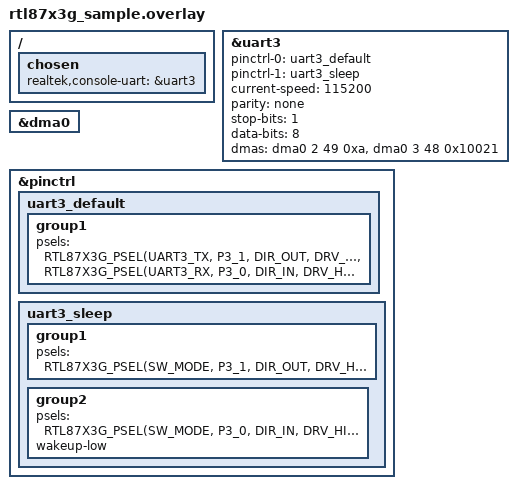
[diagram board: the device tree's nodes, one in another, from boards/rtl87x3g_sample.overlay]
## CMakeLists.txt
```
#
# Copyright (c) 2026, Realtek Semiconductor Corporation
#
# SPDX-License-Identifier: LicenseRef-Realtek-5-Clause
#

message(STATUS "CMAKELIST FOLDER: ${CMAKE_CURRENT_SOURCE_DIR}")

cmake_minimum_required(VERSION 3.20.0)

#===========version generation===========
include(${CMAKE_CURRENT_SOURCE_DIR}/../../cmake/version_generate.cmake)
generate_version()
#===========version generation===========
#===========post build===========
# post build should be called before find_package
include(${CMAKE_CURRENT_SOURCE_DIR}/../../cmake/post_build.cmake)
rtk_post_build()
#===========post build===========

find_package(Zephyr REQUIRED HINTS $ENV{ZEPHYR_BASE})
project(bt_audio)

FILE(GLOB app_sources src/*.c)
target_sources(app PRIVATE
  ${app_sources}
  )

set(sources
   ${ZEPHYR_REALTEK_APP_MODULE_DIR}/common/console/transport/console_uart.c
   )

set(headers
    #header files from app
	  src/
    #header files from libs
    ${ZEPHYR_REALTEK_APP_MODULE_DIR}/../modules/hal/realtek/rtl87x3g/subsys/audio/inc
    ${ZEPHYR_REALTEK_APP_MODULE_DIR}/../modules/hal/realtek/rtl87x3g/subsys/console/inc
    ${ZEPHYR_REALTEK_APP_MODULE_DIR}/common/console/transport
    ${ZEPHYR_REALTEK_APP_MODULE_DIR}/samples/bt_audio
    )  

foreach(header ${headers})
    if(EXISTS ${header})
        zephyr_include_directories(${header})
    else()
        message(FATAL_ERROR "header file directory does not exist: ${header}. Current cmakelist: ${CMAKE_CURRENT_SOURCE_DIR}")
    endif()
endforeach()

foreach(src ${sources})
    if(EXISTS ${src})
        target_sources(app PRIVATE ${src})
    else()
        message(FATAL_ERROR "source file does not exist: ${src}. Current cmakelist: ${CMAKE_CURRENT_SOURCE_DIR}")
    endif()
endforeach()

target_precompile_headers(app PUBLIC
	          ${CMAKE_CURRENT_SOURCE_DIR}/src/app_flags.h
			  )

target_include_directories(app PRIVATE src)

target_compile_definitions(app PRIVATE CONFIG_SOC_SERIES_RTL8773G=1)
```

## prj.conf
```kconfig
CONFIG_SERIAL=y

# Use realtek console with uart dma 
# the dma node should be added in uart node
CONFIG_UART_ASYNC_API=y
# Use realtek console with uart interrupt
# CONFIG_UART_INTERRUPT_DRIVEN=y

CONFIG_REALTEK_SUBSYS_SYSM=y
CONFIG_REALTEK_SUBSYS_CONSOLE=y
CONFIG_REALTEK_SUBSYS_REMOTE=y
CONFIG_REALTEK_SUBSYS_BTM=y
CONFIG_REALTEK_SUBSYS_AUDIO=y
CONFIG_HEAP_MEM_POOL_SIZE=1024
```

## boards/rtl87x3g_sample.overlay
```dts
/*
 * Copyright(c) 2024, Realtek Semiconductor Corporation.
 *
 * SPDX-License-Identifier: Apache-2.0
 */

/ {
    chosen {
        /* Route the RTK console transport onto uart3 through the Zephyr async
         * UART driver. Change this phandle to move the console to any UART. */
        realtek,console-uart = &uart3;
    };
};

&uart3 {
    pinctrl-0 = <&uart3_default>;
    pinctrl-1 = <&uart3_sleep>;
    pinctrl-names = "default", "sleep";
    status = "okay";
    current-speed = <115200>;
    parity = "none";
    stop-bits = "1";
    data-bits = <8>;
    dmas = <&dma0 2 49 0xa>, <&dma0 3 48 0x10021>;
    dma-names = "rx", "tx";
};

&dma0 {
    status = "okay";
};

&pinctrl
{
    uart3_default:uart3_default {
        group1 {
            psels = <RTL87X3G_PSEL(UART3_TX, P3_1, DIR_OUT, DRV_HIGH, PULL_UP)>,
            <RTL87X3G_PSEL(UART3_RX, P3_0, DIR_IN, DRV_HIGH, PULL_UP)>;
        };
    };

    uart3_sleep:uart3_sleep {
        group1 {
            psels = <RTL87X3G_PSEL(SW_MODE, P3_1, DIR_OUT, DRV_HIGH, PULL_UP)>;
        };
        group2 {
            psels = <RTL87X3G_PSEL(SW_MODE, P3_0, DIR_IN, DRV_HIGH, PULL_UP)>;
            wakeup-low;
        };
    };
};
```

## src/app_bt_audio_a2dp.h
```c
/*
 * Copyright (c) 2026, Realtek Semiconductor Corporation
 *
 * SPDX-License-Identifier: LicenseRef-Realtek-5-Clause
 */

#ifndef _APP_BT_AUDIO_A2DP_H_
#define _APP_BT_AUDIO_A2DP_H_

#include "app_msg.h"

#ifdef __cplusplus
extern "C" {
#endif /* __cplusplus */

/** @defgroup APP_BT_AUDIO_A2DP BT Audio A2DP
* @brief APP BT Audio A2DP
* @{
*/

/*============================================================================*
 *                         Macros
 *============================================================================*/
/** @addtogroup APP_BT_AUDIO_A2DP_Exported_Macros BT Audio A2DP Exported Macros
  * @brief
  * @{
  */



/** End of APP_BT_AUDIO_A2DP_Exported_Macros
* @}
*/

/*============================================================================*
 *                         Functions
 *============================================================================*/
/** @defgroup APP_BT_AUDIO_A2DP_Exported_Functions BT Audio A2DP Exported Functions
  * @brief
  * @{
  */

void app_bt_audio_a2dp_init(uint8_t role);

void app_bt_audio_a2dp_handle_msg(T_IO_MSG msg);

bool app_bt_audio_a2dp_connect(uint8_t *bd_addr);

bool app_bt_audio_a2dp_disconnect(uint8_t *bd_addr);

bool app_bt_audio_a2dp_start(uint8_t *bd_addr);

bool app_bt_audio_a2dp_suspend(uint8_t *bd_addr);

bool app_bt_audio_a2dp_volume_up(uint8_t *bd_addr);

bool app_bt_audio_a2dp_volume_down(uint8_t *bd_addr);

/** @} End of APP_BT_AUDIO_A2DP_Exported_Functions */

/** @} End of APP_BT_AUDIO_A2DP */

#ifdef __cplusplus
}
#endif /* __cplusplus */

#endif /* _APP_BT_AUDIO_A2DP_H_ */
```

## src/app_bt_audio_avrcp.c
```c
/*
 * Copyright (c) 2026, Realtek Semiconductor Corporation
 *
 * SPDX-License-Identifier: LicenseRef-Realtek-5-Clause
 */

#include <stdio.h>
#include <string.h>
#include "trace.h"
#include "console.h"
#include "audio.h"
#include "btm.h"
#include "bt_types.h"
#include "bt_sdp.h"
#include "bt_a2dp.h"
#include "bt_avrcp.h"
#include "app_bt_audio_link.h"
#include "app_bt_audio_avrcp.h"

#if (BT_AUDIO_DEMO_ROLE == 1)
static const uint8_t avrcp_ct_sdp_record[] =
{
    //Total length
    SDP_DATA_ELEM_SEQ_HDR,
    0x3b,

    //Attribute SDP_ATTR_SRV_CLASS_ID_LIST
    SDP_UNSIGNED_TWO_BYTE,
    (uint8_t)(SDP_ATTR_SRV_CLASS_ID_LIST >> 8),
    (uint8_t)SDP_ATTR_SRV_CLASS_ID_LIST,
    SDP_DATA_ELEM_SEQ_HDR,
    0x06, //Attribute length: 6 bytes
    //Service Class #0: A/V Remote Control
    SDP_UUID16_HDR,
    (uint8_t)(UUID_AV_REMOTE_CONTROL >> 8),
    (uint8_t)(UUID_AV_REMOTE_CONTROL),
    SDP_UUID16_HDR,
    (uint8_t)(UUID_AV_REMOTE_CONTROL_CONTROLLER >> 8),
    (uint8_t)(UUID_AV_REMOTE_CONTROL_CONTROLLER & 0xff),
    //Service Class #1: A/V Remote Control Controller

    //Attribute SDP_ATTR_PROTO_DESC_LIST
    SDP_UNSIGNED_TWO_BYTE,
    (uint8_t)(SDP_ATTR_PROTO_DESC_LIST >> 8),
    (uint8_t)SDP_ATTR_PROTO_DESC_LIST,
    SDP_DATA_ELEM_SEQ_HDR,
    0x10, //Attribute length: 16 bytes
    //Protocol #0: L2CAP
    SDP_DATA_ELEM_SEQ_HDR,
    0x06, //Element length: 3 bytes
    SDP_UUID16_HDR,
    (uint8_t)(UUID_L2CAP >> 8),
    (uint8_t)(UUID_L2CAP),
    //Parameter #0 for Protocol #0: PSM = AVCTP
    SDP_UNSIGNED_TWO_BYTE,
    (uint8_t)(PSM_AVCTP >> 8),
    (uint8_t)PSM_AVCTP,
    //Protocol #1: AVCTP
    SDP_DATA_ELEM_SEQ_HDR,
    0x06, //Element length: 5 bytes
    SDP_UUID16_HDR,
    (uint8_t)(UUID_AVCTP >> 8),
    (uint8_t)(UUID_AVCTP),
    //Parameter #0 for Protocol #1: 0x0104 (v1.4)
    SDP_UNSIGNED_TWO_BYTE,
    (uint8_t)(0x0104 >> 8),
    (uint8_t)(0x0104),

    //Attribute SDP_ATTR_PROFILE_DESC_LIST
    SDP_UNSIGNED_TWO_BYTE,
    (uint8_t)(SDP_ATTR_PROFILE_DESC_LIST >> 8),
    (uint8_t)SDP_ATTR_PROFILE_DESC_LIST,
    SDP_DATA_ELEM_SEQ_HDR,
    0x08, //Attribute length: 8 bytes
    //Profile #0: A/V Remote Control
    SDP_DATA_ELEM_SEQ_HDR,
    0x06, //Element length: 6 bytes
    SDP_UUID16_HDR,
    (uint8_t)(UUID_AV_REMOTE_CONTROL >> 8),
    (uint8_t)(UUID_AV_REMOTE_CONTROL),
    //Parameter #0 for Profile #0: 0x0106 (v1.6)
    SDP_UNSIGNED_TWO_BYTE,
    (uint8_t)(0x0106 >> 8),
    (uint8_t)(0x0106),

    //Attribute SDP_ATTR_SUPPORTED_FEATURES
    SDP_UNSIGNED_TWO_BYTE,
    (uint8_t)((SDP_ATTR_SUPPORTED_FEATURES) >> 8),
    (uint8_t)(SDP_ATTR_SUPPORTED_FEATURES),
    SDP_UNSIGNED_TWO_BYTE,
    (uint8_t)(0x0003 >> 8), //Category 1 Player / Recorder, Category 2
    (uint8_t)(0x0003 & 0xff),

    //Attribute SDP_ATTR_BROWSE_GROUP_LIST
    SDP_UNSIGNED_TWO_BYTE,
    (uint8_t)(SDP_ATTR_BROWSE_GROUP_LIST >> 8),
    (uint8_t)SDP_ATTR_BROWSE_GROUP_LIST,
    SDP_DATA_ELEM_SEQ_HDR,
    0x03,
    SDP_UUID16_HDR,
    (uint8_t)(UUID_PUBLIC_BROWSE_GROUP >> 8),
    (uint8_t)UUID_PUBLIC_BROWSE_GROUP
};

static const uint8_t avrcp_tg_sdp_record[] =
{
    //Total length
    SDP_DATA_ELEM_SEQ_HDR,
    0x38,//0x46,//0x5F,

    //Attribute SDP_ATTR_SRV_CLASS_ID_LIST
    SDP_UNSIGNED_TWO_BYTE,
    (uint8_t)(SDP_ATTR_SRV_CLASS_ID_LIST >> 8),
    (uint8_t)SDP_ATTR_SRV_CLASS_ID_LIST,
    SDP_DATA_ELEM_SEQ_HDR,
    0x03, //Attribute length: 3 bytes
    //Service Class #0: A/V Remote Control Target
    SDP_UUID16_HDR,
    (uint8_t)(UUID_AV_REMOTE_CONTROL_TARGET >> 8),
    (uint8_t)(UUID_AV_REMOTE_CONTROL_TARGET),

    //Attribute SDP_ATTR_PROTO_DESC_LIST
    SDP_UNSIGNED_TWO_BYTE,
    (uint8_t)(SDP_ATTR_PROTO_DESC_LIST >> 8),
    (uint8_t)SDP_ATTR_PROTO_DESC_LIST,
    SDP_DATA_ELEM_SEQ_HDR,
    0x10, //Attribute length: 16 bytes
    //Protocol #0: L2CAP
    SDP_DATA_ELEM_SEQ_HDR,
    0x06, //Element length: 3 bytes
    SDP_UUID16_HDR,
    (uint8_t)(UUID_L2CAP >> 8),
    (uint8_t)(UUID_L2CAP),
    //Parameter #0 for Protocol #0: PSM = AVCTP
    SDP_UNSIGNED_TWO_BYTE,
    (uint8_t)(PSM_AVCTP >> 8),
    (uint8_t)PSM_AVCTP,
    //Protocol #1: AVCTP
    SDP_DATA_ELEM_SEQ_HDR,
    0x06, //Element length: 5 bytes
    SDP_UUID16_HDR,
    (uint8_t)(UUID_AVCTP >> 8),
    (uint8_t)(UUID_AVCTP),
    //Parameter #0 for Protocol #1: 0x0104 (v1.4)
    SDP_UNSIGNED_TWO_BYTE,
    (uint8_t)(0x0104 >> 8),
    (uint8_t)(0x0104),

    //Attribute SDP_ATTR_PROFILE_DESC_LIST
    SDP_UNSIGNED_TWO_BYTE,
    (uint8_t)(SDP_ATTR_PROFILE_DESC_LIST >> 8),
    (uint8_t)SDP_ATTR_PROFILE_DESC_LIST,
    SDP_DATA_ELEM_SEQ_HDR,
    0x08, //Attribute length: 8 bytes
    //Profile #0: A/V Remote Control
    SDP_DATA_ELEM_SEQ_HDR,
    0x06, //Element length: 6 bytes
    SDP_UUID16_HDR,
    (uint8_t)(UUID_AV_REMOTE_CONTROL >> 8),
    (uint8_t)(UUID_AV_REMOTE_CONTROL),
    //Parameter #0 for Profile #0: 0x0106 (v1.6)
    SDP_UNSIGNED_TWO_BYTE,
    (uint8_t)(0x0106 >> 8),
    (uint8_t)(0x0106),

    //Attribute SDP_ATTR_SUPPORTED_FEATURES
    SDP_UNSIGNED_TWO_BYTE,
    (uint8_t)((SDP_ATTR_SUPPORTED_FEATURES) >> 8),
    (uint8_t)(SDP_ATTR_SUPPORTED_FEATURES),
    SDP_UNSIGNED_TWO_BYTE,
    (uint8_t)(0x0001 >> 8), //Category 1
    (uint8_t)(0x0001 & 0xff),

    //Attribute SDP_ATTR_BROWSE_GROUP_LIST
    SDP_UNSIGNED_TWO_BYTE,
    (uint8_t)(SDP_ATTR_BROWSE_GROUP_LIST >> 8),
    (uint8_t)SDP_ATTR_BROWSE_GROUP_LIST,
    SDP_DATA_ELEM_SEQ_HDR,
    0x03,
    SDP_UUID16_HDR,
    (uint8_t)(UUID_PUBLIC_BROWSE_GROUP >> 8),
    (uint8_t)UUID_PUBLIC_BROWSE_GROUP
};
#else
static const uint8_t avrcp_ct_sdp_record[] =
{
    //Total length
    SDP_DATA_ELEM_SEQ_HDR,
    0x3B,//0x49,//0x62,

    //Attribute SDP_ATTR_SRV_CLASS_ID_LIST
    SDP_UNSIGNED_TWO_BYTE,
    (uint8_t)(SDP_ATTR_SRV_CLASS_ID_LIST >> 8),
    (uint8_t)SDP_ATTR_SRV_CLASS_ID_LIST,
    SDP_DATA_ELEM_SEQ_HDR,
    0x06, //Attribute length: 6 bytes
    //Service Class #0: A/V Remote Control
    SDP_UUID16_HDR,
    (uint8_t)(UUID_AV_REMOTE_CONTROL >> 8),
    (uint8_t)(UUID_AV_REMOTE_CONTROL),
    //Service Class #1: A/V Remote Control Controller
    SDP_UUID16_HDR,
    (uint8_t)(UUID_AV_REMOTE_CONTROL_CONTROLLER >> 8),
    (uint8_t)(UUID_AV_REMOTE_CONTROL_CONTROLLER),

    //Attribute SDP_ATTR_PROTO_DESC_LIST
    SDP_UNSIGNED_TWO_BYTE,
    (uint8_t)(SDP_ATTR_PROTO_DESC_LIST >> 8),
    (uint8_t)SDP_ATTR_PROTO_DESC_LIST,
    SDP_DATA_ELEM_SEQ_HDR,
    0x10, //Attribute length: 12 bytes
    //Protocol #0: L2CAP
    SDP_DATA_ELEM_SEQ_HDR,
    0x06, //Element length: 3 bytes
    SDP_UUID16_HDR,
    (uint8_t)(UUID_L2CAP >> 8),
    (uint8_t)(UUID_L2CAP),
    //Parameter #0 for Protocol #0: PSM = AVCTP
    SDP_UNSIGNED_TWO_BYTE,
    (uint8_t)(PSM_AVCTP >> 8),
    (uint8_t)PSM_AVCTP,
    //Protocol #1: AVCTP
    SDP_DATA_ELEM_SEQ_HDR,
    0x06, //Element length: 5 bytes
    SDP_UUID16_HDR,
    (uint8_t)(UUID_AVCTP >> 8),
    (uint8_t)(UUID_AVCTP),
    //Parameter #0 for Protocol #1: 0x0104 (v1.4)
    SDP_UNSIGNED_TWO_BYTE,
    (uint8_t)(0x0104 >> 8),
    (uint8_t)(0x0104),

    //Attribute SDP_ATTR_PROFILE_DESC_LIST
    SDP_UNSIGNED_TWO_BYTE,
    (uint8_t)(SDP_ATTR_PROFILE_DESC_LIST >> 8),
    (uint8_t)SDP_ATTR_PROFILE_DESC_LIST,
    SDP_DATA_ELEM_SEQ_HDR,
    0x08, //Attribute length: 8 bytes
    //Profile #0: A/V Remote Control
    SDP_DATA_ELEM_SEQ_HDR,
    0x06, //Element length: 6 bytes
    SDP_UUID16_HDR,
    (uint8_t)(UUID_AV_REMOTE_CONTROL >> 8),
    (uint8_t)(UUID_AV_REMOTE_CONTROL),
    //Parameter #0 for Profile #0: 0x0106 (v1.6)
    SDP_UNSIGNED_TWO_BYTE,
    (uint8_t)(0x0106 >> 8),
    (uint8_t)(0x0106),

    //Attribute SDP_ATTR_SUPPORTED_FEATURES
    SDP_UNSIGNED_TWO_BYTE,
    (uint8_t)((SDP_ATTR_SUPPORTED_FEATURES) >> 8),
    (uint8_t)(SDP_ATTR_SUPPORTED_FEATURES),
    SDP_UNSIGNED_TWO_BYTE,
    (uint8_t)(0x0001 >> 8), //Category 1 Player / Recorder
    (uint8_t)(0x0001),

    //Attribute SDP_ATTR_BROWSE_GROUP_LIST
    SDP_UNSIGNED_TWO_BYTE,
    (uint8_t)(SDP_ATTR_BROWSE_GROUP_LIST >> 8),
    (uint8_t)SDP_ATTR_BROWSE_GROUP_LIST,
    SDP_DATA_ELEM_SEQ_HDR,
    0x03,
    SDP_UUID16_HDR,
    (uint8_t)(UUID_PUBLIC_BROWSE_GROUP >> 8),
    (uint8_t)UUID_PUBLIC_BROWSE_GROUP
    /*
        //Attribute SDP_ATTR_LANG_BASE_ATTR_ID_LIST...it is used for SDP_ATTR_SRV_NAME
        SDP_UNSIGNED_TWO_BYTE,
        (uint8_t)(SDP_ATTR_LANG_BASE_ATTR_ID_LIST >> 8),
        (uint8_t)SDP_ATTR_LANG_BASE_ATTR_ID_LIST,
        SDP_DATA_ELEM_SEQ_HDR,
        0x09,
        SDP_UNSIGNED_TWO_BYTE,
        (uint8_t)(SDP_LANG_ENGLISH >> 8),
        (uint8_t)SDP_LANG_ENGLISH,
        SDP_UNSIGNED_TWO_BYTE,
        (uint8_t)(SDP_CHARACTER_UTF8 >> 8),
        (uint8_t)SDP_CHARACTER_UTF8,
        SDP_UNSIGNED_TWO_BYTE,
        (uint8_t)(SDP_BASE_LANG_OFFSET >> 8),
        (uint8_t)SDP_BASE_LANG_OFFSET,

        //Attribute SDP_ATTR_PROVIDER_NAME
        SDP_UNSIGNED_TWO_BYTE,
        (uint8_t)((SDP_ATTR_PROVIDER_NAME + SDP_BASE_LANG_OFFSET) >> 8),
        (uint8_t)(SDP_ATTR_PROVIDER_NAME + SDP_BASE_LANG_OFFSET),
        SDP_STRING_HDR,
        0x07, //Attribute length: 7 bytes
        0x52, 0x65, 0x61, 0x6C, 0x54, 0x65, 0x6B, //RealTek

        //Attribute SDP_ATTR_SRV_NAME
        SDP_UNSIGNED_TWO_BYTE,
        (uint8_t)((SDP_ATTR_SRV_NAME + SDP_BASE_LANG_OFFSET) >> 8),
        (uint8_t)(SDP_ATTR_SRV_NAME + SDP_BASE_LANG_OFFSET),
        SDP_STRING_HDR,
        0x08, //Attribute length: 8 bytes
        0x41, 0x56, 0x52, 0x43, 0x50, 0x20, 0x43, 0x54, //AVRCP CT
    */
};

static const uint8_t avrcp_tg_sdp_record[] =
{
    //Total length
    SDP_DATA_ELEM_SEQ_HDR,
    0x38,//0x46,//0x5F,

    //Attribute SDP_ATTR_SRV_CLASS_ID_LIST
    SDP_UNSIGNED_TWO_BYTE,
    (uint8_t)(SDP_ATTR_SRV_CLASS_ID_LIST >> 8),
    (uint8_t)SDP_ATTR_SRV_CLASS_ID_LIST,
    SDP_DATA_ELEM_SEQ_HDR,
    0x03, //Attribute length: 6 bytes
    //Service Class #0: A/V Remote Control Target
    SDP_UUID16_HDR,
    (uint8_t)(UUID_AV_REMOTE_CONTROL_TARGET >> 8),
    (uint8_t)(UUID_AV_REMOTE_CONTROL_TARGET),

    //Attribute SDP_ATTR_PROTO_DESC_LIST
    SDP_UNSIGNED_TWO_BYTE,
    (uint8_t)(SDP_ATTR_PROTO_DESC_LIST >> 8),
    (uint8_t)SDP_ATTR_PROTO_DESC_LIST,
    SDP_DATA_ELEM_SEQ_HDR,
    0x10, //Attribute length: 12 bytes
    //Protocol #0: L2CAP
    SDP_DATA_ELEM_SEQ_HDR,
    0x06, //Element length: 3 bytes
    SDP_UUID16_HDR,
    (uint8_t)(UUID_L2CAP >> 8),
    (uint8_t)(UUID_L2CAP),
    //Parameter #0 for Protocol #0: PSM = AVCTP
    SDP_UNSIGNED_TWO_BYTE,
    (uint8_t)(PSM_AVCTP >> 8),
    (uint8_t)PSM_AVCTP,
    //Protocol #1: AVCTP
    SDP_DATA_ELEM_SEQ_HDR,
    0x06, //Element length: 5 bytes
    SDP_UUID16_HDR,
    (uint8_t)(UUID_AVCTP >> 8),
    (uint8_t)(UUID_AVCTP),
    //Parameter #0 for Protocol #1: 0x0104 (v1.4)
    SDP_UNSIGNED_TWO_BYTE,
    (uint8_t)(0x0104 >> 8),
    (uint8_t)(0x0104),

    //Attribute SDP_ATTR_PROFILE_DESC_LIST
    SDP_UNSIGNED_TWO_BYTE,
    (uint8_t)(SDP_ATTR_PROFILE_DESC_LIST >> 8),
    (uint8_t)SDP_ATTR_PROFILE_DESC_LIST,
    SDP_DATA_ELEM_SEQ_HDR,
    0x08, //Attribute length: 8 bytes
    //Profile #0: A/V Remote Control
    SDP_DATA_ELEM_SEQ_HDR,
    0x06, //Element length: 6 bytes
    SDP_UUID16_HDR,
    (uint8_t)(UUID_AV_REMOTE_CONTROL >> 8),
    (uint8_t)(UUID_AV_REMOTE_CONTROL),
    //Parameter #0 for Profile #0: 0x0106 (v1.6)
    SDP_UNSIGNED_TWO_BYTE,
    (uint8_t)(0x0106 >> 8),
    (uint8_t)(0x0106),

    //Attribute SDP_ATTR_SUPPORTED_FEATURES
    SDP_UNSIGNED_TWO_BYTE,
    (uint8_t)((SDP_ATTR_SUPPORTED_FEATURES) >> 8),
    (uint8_t)(SDP_ATTR_SUPPORTED_FEATURES),
    SDP_UNSIGNED_TWO_BYTE,
    (uint8_t)(0x0002 >> 8), //Category 2 Amplifier
    (uint8_t)(0x0002),

    //Attribute SDP_ATTR_BROWSE_GROUP_LIST
    SDP_UNSIGNED_TWO_BYTE,
    (uint8_t)(SDP_ATTR_BROWSE_GROUP_LIST >> 8),
    (uint8_t)SDP_ATTR_BROWSE_GROUP_LIST,
    SDP_DATA_ELEM_SEQ_HDR,
    0x03,
    SDP_UUID16_HDR,
    (uint8_t)(UUID_PUBLIC_BROWSE_GROUP >> 8),
    (uint8_t)UUID_PUBLIC_BROWSE_GROUP
    /*
        //Attribute SDP_ATTR_LANG_BASE_ATTR_ID_LIST...it is used for SDP_ATTR_SRV_NAME
        SDP_UNSIGNED_TWO_BYTE,
        (uint8_t)(SDP_ATTR_LANG_BASE_ATTR_ID_LIST >> 8),
        (uint8_t)SDP_ATTR_LANG_BASE_ATTR_ID_LIST,
        SDP_DATA_ELEM_SEQ_HDR,
        0x09,
        SDP_UNSIGNED_TWO_BYTE,
        (uint8_t)(SDP_LANG_ENGLISH >> 8),
        (uint8_t)SDP_LANG_ENGLISH,
        SDP_UNSIGNED_TWO_BYTE,
        (uint8_t)(SDP_CHARACTER_UTF8 >> 8),
        (uint8_t)SDP_CHARACTER_UTF8,
        SDP_UNSIGNED_TWO_BYTE,
        (uint8_t)(SDP_BASE_LANG_OFFSET >> 8),
        (uint8_t)SDP_BASE_LANG_OFFSET,

        //Attribute SDP_ATTR_PROVIDER_NAME
        SDP_UNSIGNED_TWO_BYTE,
        (uint8_t)((SDP_ATTR_PROVIDER_NAME + SDP_BASE_LANG_OFFSET) >> 8),
        (uint8_t)(SDP_ATTR_PROVIDER_NAME + SDP_BASE_LANG_OFFSET),
        SDP_STRING_HDR,
        0x07, //Attribute length: 7 bytes
        0x52, 0x65, 0x61, 0x6C, 0x54, 0x65, 0x6B, //RealTek

        //Attribute SDP_ATTR_SRV_NAME
        SDP_UNSIGNED_TWO_BYTE,
        (uint8_t)((SDP_ATTR_SRV_NAME + SDP_BASE_LANG_OFFSET) >> 8),
        (uint8_t)(SDP_ATTR_SRV_NAME + SDP_BASE_LANG_OFFSET),
        SDP_STRING_HDR,
        0x08, //Attribute length: 8 bytes
        0x41, 0x56, 0x52, 0x43, 0x50, 0x20, 0x54, 0x47, //AVRCP TG
    */
};
#endif

static void app_bt_audio_avrcp_cback(T_BT_EVENT event_type, void *event_buf, uint16_t buf_len)
{
    T_BT_EVENT_PARAM *param = event_buf;
    T_APP_BT_AUDIO_LINK *p_link;

    switch (event_type)
    {
    case BT_EVENT_AVRCP_CONN_IND:
        p_link = app_bt_audio_find_link(param->avrcp_conn_ind.bd_addr);
        if (p_link != NULL)
        {
            bt_avrcp_connect_cfm(p_link->bd_addr, true);
        }
        break;

    case BT_EVENT_AVRCP_CONN_CMPL:
        {
            char *temp_buff = "AVRCP Connected!\r\n";
            console_write((uint8_t *)temp_buff, strlen(temp_buff));

            memcpy(app_db.remote_addr, param->avrcp_conn_cmpl.bd_addr, 6);
        }
        break;

    case BT_EVENT_AVRCP_DISCONN_CMPL:
        break;

    case BT_EVENT_AVRCP_GET_CAPABILITIES_RSP:
        {
            p_link = app_bt_audio_find_link(param->avrcp_browsing_conn_ind.bd_addr);
            if (p_link != NULL)
            {
                uint8_t  capability_count;
                uint8_t *capabilities;

                capability_count = param->avrcp_get_capabilities_rsp.capability_count;
                capabilities = param->avrcp_get_capabilities_rsp.capabilities;
                while (capability_count != 0)
                {
                    bt_avrcp_register_notification_req(p_link->bd_addr, *capabilities);
                    capability_count -= 1;
                    capabilities += 1;
                }
            }
        }
        break;

    case BT_EVENT_AVRCP_PLAY_STATUS_CHANGED_REG_REQ:
        p_link = app_bt_audio_find_link(param->avrcp_reg_play_status_changed.bd_addr);
        if (p_link != NULL)
        {
            if (p_link->is_streaming)
            {
                bt_avrcp_play_status_change_register_rsp(p_link->bd_addr, BT_AVRCP_PLAY_STATUS_PLAYING);
            }
            else
            {
                bt_avrcp_play_status_change_register_rsp(p_link->bd_addr, BT_AVRCP_PLAY_STATUS_PAUSED);
            }
        }
        break;

    case BT_EVENT_AVRCP_PLAY_STATUS_CHANGED:
        p_link = app_bt_audio_find_link(param->avrcp_play_status_changed.bd_addr);
        if (p_link != NULL)
        {
            p_link->avrcp_play_status = param->avrcp_play_status_changed.play_status;
        }
        break;

    case BT_EVENT_AVRCP_PLAY:
        break;

    case BT_EVENT_AVRCP_PAUSE:
        break;

    case BT_EVENT_AVRCP_ABSOLUTE_VOLUME_SET:
        p_link = app_bt_audio_find_link(param->avrcp_absolute_volume_set.bd_addr);
        if (p_link != NULL)
        {
            p_link->a2dp_curr_volume = (param->avrcp_absolute_volume_set.volume *
                                        A2DP_VOLUME_MAX_LEVEL + 0x7F / 2) / 0x7F;

            if (p_link->a2dp_track_handle)
            {
                audio_track_volume_out_set(p_link->a2dp_track_handle, p_link->a2dp_curr_volume);
            }
        }
        break;

    case BT_EVENT_AVRCP_REG_VOLUME_CHANGED:
        p_link = app_bt_audio_find_link(param->avrcp_reg_volume_changed.bd_addr);
        if (p_link != NULL)
        {
            uint8_t vol = (p_link->a2dp_curr_volume * 0x7F + A2DP_VOLUME_MAX_LEVEL / 2) /
                          A2DP_VOLUME_MAX_LEVEL;

            bt_avrcp_volume_change_register_rsp(p_link->bd_addr, vol);
        }
        break;

    case BT_EVENT_SDP_ATTR_INFO:
        {
            T_BT_SDP_ATTR_INFO *sdp_info = &param->sdp_attr_info.info;

            if (app_db.a2dp_role == BT_A2DP_ROLE_SNK)
            {
                if (sdp_info->srv_class_uuid_data.uuid_16 == UUID_AV_REMOTE_CONTROL_TARGET)
                {
                    uint8_t *p_attr;

                    p_attr = bt_sdp_attr_find(sdp_info->p_attr,
                                              sdp_info->attr_len,
                                              SDP_ATTR_ADD_PROTO_DESC_LIST);
                    if (p_attr)
                    {
                        uint8_t *p_attr_param;
                        uint8_t *p_elem;
                        uint8_t  loop;
                        uint16_t uuid_1;
                        uint16_t uuid_2;
                        uint16_t l2c_psm;

                        loop = 1;
                        while ((p_elem = bt_sdp_elem_access(p_attr, sdp_info->attr_len, loop)) != NULL)
                        {
                            p_attr_param = bt_sdp_elem_access(p_elem, sdp_info->attr_len, 2);
                            if (p_attr_param)
                            {
                                p_attr_param = bt_sdp_elem_access(p_elem, sdp_info->attr_len, 1);

                                uuid_1 = p_attr_param[3] << 8 | p_attr_param[4];
                                uuid_2 = p_attr_param[11] << 8 | p_attr_param[12];
                                if (uuid_1 == UUID_L2CAP && uuid_2 == UUID_OBEX)
                                {
                                    l2c_psm = p_attr_param[6] << 8 | p_attr_param[7];
                                    bt_avrcp_cover_art_connect_req(param->sdp_attr_info.bd_addr, l2c_psm);
                                    break;
                                }
                            }
                            loop++;
                        }
                    }
                }
            }
        }
        break;

    case BT_EVENT_AVRCP_COVER_ART_CONN_CMPL:
        {
            char *temp_buff = "AVRCP Cover Art Connected!\r\n";
            console_write((uint8_t *)temp_buff, strlen(temp_buff));
        }
        break;

    case BT_EVENT_AVRCP_COVER_ART_DISCONN_CMPL:
        {
            char *temp_buff = "AVRCP Cover Art Disconnected!\r\n";
            console_write((uint8_t *)temp_buff, strlen(temp_buff));
        }
        break;

    case BT_EVENT_AVRCP_ELEM_ATTR:
        p_link = app_bt_audio_find_link(param->avrcp_elem_attr.bd_addr);
        if (p_link != NULL)
        {
            if (param->avrcp_elem_attr.state == 0)
            {
                const char *attr[] = {"", "Title:", "Artist:", "Album:", "Track:",
                                      "TotalTrack:", "Genre:", "PlayingTime:"
                                     };
                uint8_t  temp_buff[50];
                uint16_t buf_len;
                uint8_t  attr_id;
                uint8_t  i, j;

                for (i = 0; i < param->avrcp_elem_attr.num_of_attr; i++)
                {
                    attr_id = param->avrcp_elem_attr.attr[i].attribute_id;
                    if (attr_id != BT_AVRCP_ELEM_ATTR_DEFAULT_COVER_ART)
                    {
                        snprintf((char *)temp_buff, 50, "%s%s\r\n", attr[attr_id],
                                 param->avrcp_elem_attr.attr[i].p_buf);

                        buf_len = param->avrcp_elem_attr.attr[i].length + sizeof(attr[attr_id]) + 2;
                        if (buf_len < 50)
                        {
                            console_write(temp_buff, buf_len);
                        }
                        else
                        {
                            console_write(temp_buff, 50);
                        }
                    }
                    else
                    {
                        uint8_t image_handle[16] = {0};

                        for (j = 0; j < param->avrcp_elem_attr.attr[i].length; j++)
                        {
                            image_handle[2 * j + 1] = param->avrcp_elem_attr.attr[i].p_buf[j];
                        }

                        bt_avrcp_cover_art_get(p_link->bd_addr, image_handle);
                    }
                }
            }
        }
        break;

    case BT_EVENT_AVRCP_COVER_ART_DATA_IND:
        p_link = app_bt_audio_find_link(param->avrcp_cover_art_data_ind.bd_addr);
        if (p_link != NULL)
        {
            if (!param->avrcp_cover_art_data_ind.data_end)
            {
                bt_avrcp_cover_art_get(p_link->bd_addr, NULL);
            }
            else
            {
                char *temp_buff = "AVRCP Cover Art Get Success!\r\n";
                console_write((uint8_t *)temp_buff, strlen(temp_buff));
            }
        }
        break;

    default:
        break;
    }
}

void app_bt_audio_avrcp_init(void)
{
    int32_t ret = 0;

    bt_sdp_record_add((void *)avrcp_ct_sdp_record);
    bt_sdp_record_add((void *)avrcp_tg_sdp_record);

    //if absolute volume is supported
#if (BT_AUDIO_DEMO_ROLE == 1)
    if (bt_avrcp_init(BT_AVRCP_FEATURE_CATEGORY_1 | BT_AVRCP_FEATURE_CATEGORY_2,
                      BT_AVRCP_FEATURE_CATEGORY_1) == false)
    {
        ret = -1;
        goto fail_init;
    }
#else
    if (bt_avrcp_init(BT_AVRCP_FEATURE_CATEGORY_1, BT_AVRCP_FEATURE_CATEGORY_2) == false)
    {
        ret = -1;
        goto fail_init;
    }
#endif

    bt_mgr_cback_register(app_bt_audio_avrcp_cback);

    return;

fail_init:
    APP_PRINT_ERROR1("app_bt_audio_avrcp_init: failed %d", ret);
}

bool app_bt_audio_avrcp_element_attr_get(uint8_t *bd_addr, uint8_t attr_id)
{
    T_APP_BT_AUDIO_LINK *p_link;

    p_link = app_bt_audio_find_link(bd_addr);
    if (p_link != NULL)
    {
        return bt_avrcp_get_element_attr_req(bd_addr, 1, &attr_id);
    }

    return false;
}

bool app_bt_audio_avrcp_cover_art_connect(uint8_t *bd_addr)
{
    T_BT_SDP_UUID_DATA uuid;

    uuid.uuid_16 = UUID_AV_REMOTE_CONTROL_TARGET;

    return bt_sdp_discov_start(bd_addr, BT_SDP_UUID16, uuid);
}

bool app_bt_audio_avrcp_cover_art_disconnect(uint8_t *bd_addr)
{
    T_APP_BT_AUDIO_LINK *p_link;

    p_link = app_bt_audio_find_link(bd_addr);
    if (p_link != NULL)
    {
        return bt_avrcp_cover_art_disconnect_req(bd_addr);
    }

    return false;
}

bool app_bt_audio_avrcp_cover_art_get(uint8_t *bd_addr)
{
    T_APP_BT_AUDIO_LINK *p_link;

    p_link = app_bt_audio_find_link(bd_addr);
    if (p_link != NULL)
    {
        uint8_t attr = BT_AVRCP_ELEM_ATTR_DEFAULT_COVER_ART;

        return bt_avrcp_get_element_attr_req(bd_addr, 1, &attr);
    }

    return false;
}
```

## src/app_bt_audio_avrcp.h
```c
/*
 * Copyright (c) 2026, Realtek Semiconductor Corporation
 *
 * SPDX-License-Identifier: LicenseRef-Realtek-5-Clause
 */

#ifndef _APP_BT_AUDIO_AVRCP_H_
#define _APP_BT_AUDIO_AVRCP_H_

#ifdef __cplusplus
extern "C" {
#endif /* __cplusplus */

/** @defgroup APP_BT_AUDIO_AVRCP BT Audio AVRCP
* @brief APP BT Audio AVRCP
* @{
*/

/*============================================================================*
 *                         Functions
 *============================================================================*/
/** @defgroup APP_BT_AUDIO_AVRCP_Exported_Functions BT Audio AVRCP Exported Functions
  * @brief
  * @{
  */

/**
    * @brief  AVRCP init
    * @param  void
    * @return void
    */
void app_bt_audio_avrcp_init(void);

bool app_bt_audio_avrcp_cover_art_connect(uint8_t *bd_addr);

bool app_bt_audio_avrcp_cover_art_disconnect(uint8_t *bd_addr);

bool app_bt_audio_avrcp_cover_art_get(uint8_t *bd_addr);

bool app_bt_audio_avrcp_element_attr_get(uint8_t *bd_addr, uint8_t attr_id);

/** @} End of APP_BT_AUDIO_AVRCP_Exported_Functions */

/** @} End of APP_BT_AUDIO_AVRCP */

#ifdef __cplusplus
}
#endif /* __cplusplus */

#endif /* _APP_BT_AUDIO_AVRCP_H_ */
```

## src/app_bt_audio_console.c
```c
/*
 * Copyright (c) 2026, Realtek Semiconductor Corporation
 *
 * SPDX-License-Identifier: LicenseRef-Realtek-5-Clause
 */

#include <stdio.h>
#include <stdlib.h>
#include <stdint.h>
#include <stdbool.h>
#include <string.h>
#include "trace.h"
#include "os_mem.h"
#include "cli.h"
#include "bt_types.h"
#include "app_io_msg.h"
#include "app_bt_audio_console.h"

bool app_bt_audio_send_msg(T_IO_CONSOLE subtype, void *param_buf)
{
    T_IO_MSG msg;

    msg.type    = IO_MSG_TYPE_CONSOLE;
    msg.subtype = subtype;
    msg.u.buf   = param_buf;

    return app_io_send_msg(&msg);
}

bool console_bredr(const char *cmd_str, char *buf, size_t buf_len)
{
    char       *subcmd;
    char       *p_param;
    int32_t     param_num;
    uint32_t    param_len;
    uint8_t     action;
    uint8_t     addr[6];
    uint8_t     i;
    uint8_t     value;
    void       *param_buf;

    param_num = cli_param_num_get(cmd_str);
    if (param_num < 1)
    {
        subcmd = (char *)cmd_str;
        goto err;
    }

    subcmd = (char *)cli_param_get(cmd_str, 1, &param_len);
    subcmd[param_len] = '\0';

    if (!strcmp(subcmd, "addr_set"))
    {
        subcmd += param_len + 1;

        subcmd = (char *)cli_param_get(subcmd, 0, &param_len);
        subcmd[param_len] = '\0';

        if (!strcmp(subcmd, "local"))
        {
            action = BT_AUDIO_ACTION_BREDR_LOCAL_ADDR_SET;
        }
        else if (!strcmp(subcmd, "remote"))
        {
            action = BT_AUDIO_ACTION_BREDR_REMOTE_ADDR_SET;
        }
        else
        {
            goto err;
        }

        p_param = subcmd + param_len + 1;

        for (i = 0; i < 6; i++)
        {
            addr[i] = (uint8_t)strtol(cli_param_get(p_param, i, &param_len), NULL, 0);
        }
    }
    else if (!strcmp(subcmd, "inquiry"))
    {
        action = BT_AUDIO_ACTION_BREDR_INQUIRY_START;
    }
    else if (!strcmp(subcmd, "name_set"))
    {
        action = BT_AUDIO_ACTION_BREDR_NAME_SET;
    }
    else if (!strcmp(subcmd, "device_mode_set"))
    {
        subcmd += param_len + 1;

        subcmd = (char *)cli_param_get(subcmd, 0, &param_len);
        subcmd[param_len] = '\0';

        if (!strcmp(subcmd, "idle"))
        {
            value = 0;
            action = BT_AUDIO_ACTION_BREDR_DEVICE_MODE_SET;
        }
        else if (!strcmp(subcmd, "discoverable"))
        {
            value = 1;
            action = BT_AUDIO_ACTION_BREDR_DEVICE_MODE_SET;
        }
        else if (!strcmp(subcmd, "connectable"))
        {
            value = 2;
            action = BT_AUDIO_ACTION_BREDR_DEVICE_MODE_SET;
        }
        else if (!strcmp(subcmd, "discoverable_connectable"))
        {
            value = 3;
            action = BT_AUDIO_ACTION_BREDR_DEVICE_MODE_SET;
        }
        else
        {
            goto err;
        }
    }
    else
    {
        goto err;
    }

    param_buf = malloc(40);
    if (param_buf != NULL)
    {
        uint8_t    *p;

        p = param_buf;
        LE_UINT16_TO_STREAM(p, GAP_BREDR_ID);
        LE_UINT8_TO_STREAM(p, action);

        if ((action == BT_AUDIO_ACTION_BREDR_LOCAL_ADDR_SET) ||
            (action == BT_AUDIO_ACTION_BREDR_REMOTE_ADDR_SET))
        {
            ARRAY_TO_STREAM(p, addr, 6);
        }
        else if (action == BT_AUDIO_ACTION_BREDR_NAME_SET)
        {
            uint8_t  len;
            len  = buf_len - param_len - 1;
            if (len + 4 > 40)
            {
                LE_UINT8_TO_STREAM(p, 40 - 4);
                ARRAY_TO_STREAM(p, subcmd + param_len + 1, 40 - 4);
            }
            else
            {
                LE_UINT8_TO_STREAM(p, len);
                ARRAY_TO_STREAM(p, subcmd + param_len + 1, len);
            }
        }
        else if (action == BT_AUDIO_ACTION_BREDR_DEVICE_MODE_SET)
        {
            LE_UINT8_TO_STREAM(p, value);
        }

        if (app_bt_audio_send_msg(IO_MSG_CONSOLE_STRING_RX, param_buf) == false)
        {
            free(param_buf);
            goto err;
        }
    }

    snprintf(buf, buf_len, "BREDR %s from bt audio.\r\n", subcmd);
    return false;

err:
    snprintf(buf, buf_len, "Invalid param %s.\r\n", subcmd);
    return false;
}

static T_CLI_CMD bt_audio_cmd_bredr =
{
    NULL,           /* Next command pointed to NULL. */
    NULL,           /* Next subcommand. */
    "bredr",         /* The command string to type. */
    "\r\nbredr:\r\n configure Bluetooth bredr param\r\n\r\n",
    console_bredr,   /* The function to run. */
    -1              /* Zero or more parameters are expected. */
};

bool console_a2dp(const char *cmd_str, char *buf, size_t buf_len)
{
    char       *subcmd;
    int32_t     param_num;
    uint32_t    param_len;
    uint8_t     action;
    void       *param_buf;

    param_num = cli_param_num_get(cmd_str);
    if (param_num < 1)
    {
        subcmd = (char *)cmd_str;
        goto err;
    }

    subcmd = (char *)cli_param_get(cmd_str, 1, &param_len);
    subcmd[param_len] = '\0';

    if (!strcmp(subcmd, "connect"))
    {
        action = BT_AUDIO_ACTION_A2DP_CONNECT;
    }
    else if (!strcmp(subcmd, "disconnect"))
    {
        action = BT_AUDIO_ACTION_A2DP_DISCONNECT;
    }
    else if (!strcmp(subcmd, "start"))
    {
        action = BT_AUDIO_ACTION_A2DP_START;
    }
    else if (!strcmp(subcmd, "suspend"))
    {
        action = BT_AUDIO_ACTION_A2DP_SUSPEND;
    }
    else if (!strcmp(subcmd, "vol+"))
    {
        action = BT_AUDIO_ACTION_A2DP_VOLUME_UP;
    }
    else if (!strcmp(subcmd, "vol-"))
    {
        action = BT_AUDIO_ACTION_A2DP_VOLUME_DOWN;
    }
    else
    {
        goto err;
    }

    param_buf = malloc(40);
    if (param_buf != NULL)
    {
        uint8_t    *p;

        p = param_buf;
        LE_UINT16_TO_STREAM(p, A2DP_ID);
        LE_UINT8_TO_STREAM(p, action);

        if (app_bt_audio_send_msg(IO_MSG_CONSOLE_STRING_RX, param_buf) == false)
        {
            free(param_buf);
            goto err;
        }

        snprintf(buf, buf_len, "A2DP %s from bt audio.\r\n", subcmd);
    }

    return false;

err:
    snprintf(buf, buf_len, "Invalid param %s (a2dp connect/disconnect).\r\n", subcmd);
    return false;
}

static T_CLI_CMD bt_audio_cmd_a2dp =
{
    NULL,           /* Next command pointed to NULL. */
    NULL,           /* Next subcommand. */
    "a2dp",         /* The command string to type. */
    "\r\na2dp:\r\n a2dp demo start\r\n\r\n",
    console_a2dp,   /* The function to run. */
    -1              /* Zero or more parameters are expected. */
};

bool console_avrcp(const char *cmd_str, char *buf, size_t buf_len)
{
    char       *subcmd;
    char       *p_param;
    int32_t     param_num;
    uint32_t    param_len;
    uint8_t     action;
    uint8_t     attr_id;
    void       *param_buf;

    param_num = cli_param_num_get(cmd_str);
    if (param_num < 1)
    {
        subcmd = (char *)cmd_str;
        goto err;
    }

    subcmd = (char *)cli_param_get(cmd_str, 1, &param_len);
    subcmd[param_len] = '\0';

    if (!strcmp(subcmd, "cover_art_connect"))
    {
        action = BT_AUDIO_ACTION_AVRCP_COVER_ART_CONNECT;
    }
    else if (!strcmp(subcmd, "cover_art_disconnect"))
    {
        action = BT_AUDIO_ACTION_AVRCP_COVER_ART_DISCONNECT;
    }
    else if (!strcmp(subcmd, "cover_art_get"))
    {
        action = BT_AUDIO_ACTION_AVRCP_COVER_ART_GET;
    }
    else if (!strcmp(subcmd, "attr_get"))
    {
        if (param_num != 2)
        {
            goto err;
        }

        p_param = subcmd + param_len + 1;

        attr_id = (uint8_t)strtol(cli_param_get(p_param, 0, &param_len), NULL, 0);

        action = BT_AUDIO_ACTION_AVRCP_ELEM_ATTR_GET;
    }
    else
    {
        goto err;
    }

    param_buf = malloc(40);
    if (param_buf != NULL)
    {
        uint8_t    *p;

        p = param_buf;
        LE_UINT16_TO_STREAM(p, AVRCP_ID);
        LE_UINT8_TO_STREAM(p, action);
        if (action == BT_AUDIO_ACTION_AVRCP_ELEM_ATTR_GET)
        {
            LE_UINT8_TO_STREAM(p, attr_id);
        }

        if (app_bt_audio_send_msg(IO_MSG_CONSOLE_STRING_RX, param_buf) == false)
        {
            free(param_buf);
            goto err;
        }

        snprintf(buf, buf_len, "AVRCP %s from bt audio.\r\n", subcmd);
    }

    return false;

err:
    snprintf(buf, buf_len, "Invalid param %s (avrcp connect/disconnect).\r\n", subcmd);
    return false;
}

static T_CLI_CMD bt_audio_cmd_avrcp =
{
    NULL,           /* Next command pointed to NULL. */
    NULL,           /* Next subcommand. */
    "avrcp",         /* The command string to type. */
    "\r\navrcp:\r\n avrcp demo start\r\n\r\n",
    console_avrcp,   /* The function to run. */
    -1              /* Zero or more parameters are expected. */
};

bool console_hfp(const char *cmd_str, char *buf, size_t buf_len)
{
    char       *subcmd;
    int32_t     param_num;
    uint32_t    param_len;
    uint8_t     action;
    void       *param_buf;

    param_num = cli_param_num_get(cmd_str);
    if (param_num < 1)
    {
        subcmd = (char *)cmd_str;
        goto err;
    }

    subcmd = (char *)cli_param_get(cmd_str, 1, &param_len);
    subcmd[param_len] = '\0';

    if (!strcmp(subcmd, "connect"))
    {
        action = BT_AUDIO_ACTION_HFP_CONNECT;
    }
    else if (!strcmp(subcmd, "disconnect"))
    {
        action = BT_AUDIO_ACTION_HFP_DISCONNECT;
    }
    else if (!strcmp(subcmd, "sco_connect"))
    {
        action = BT_AUDIO_ACTION_HFP_SCO_CONNECT;
    }
    else if (!strcmp(subcmd, "call_incoming"))
    {
        action = BT_AUDIO_ACTION_HFP_CALL_INCOMING;
    }
    else if (!strcmp(subcmd, "call_answer"))
    {
        action = BT_AUDIO_ACTION_HFP_CALL_ANSWER;
    }
    else if (!strcmp(subcmd, "call_terminate"))
    {
        action = BT_AUDIO_ACTION_HFP_CALL_TERMINATE;
    }
    else if (!strcmp(subcmd, "sco_disconnect"))
    {
        action = BT_AUDIO_ACTION_HFP_SCO_DISCONNECT;
    }
    else if (!strcmp(subcmd, "vendor_at_cmd"))
    {
        action = BT_AUDIO_ACTION_HFP_VENDOR_AT_CMD;
    }
    else
    {
        goto err;
    }

    param_buf = malloc(40);
    if (param_buf != NULL)
    {
        uint8_t    *p;

        p = param_buf;
        LE_UINT16_TO_STREAM(p, HFP_ID);
        LE_UINT8_TO_STREAM(p, action);

        if (app_bt_audio_send_msg(IO_MSG_CONSOLE_STRING_RX, param_buf) == false)
        {
            free(param_buf);
            goto err;
        }

        snprintf(buf, buf_len, "HFP %s from bt audio.\r\n", subcmd);
    }

    return false;

err:
    snprintf(buf, buf_len, "Invalid param %s (hfp connect/disconnect).\r\n", subcmd);
    return false;
}

static T_CLI_CMD bt_audio_cmd_hfp =
{
    NULL,           /* Next command pointed to NULL. */
    NULL,           /* Next subcommand. */
    "hfp",          /* The command string to type. */
    "\r\nhfp:\r\n hfp demo start\r\n\r\n",
    console_hfp,    /* The function to run. */
    -1              /* Zero or more parameters are expected. */
};

void app_bt_audio_cmd_register(void)
{
    cli_cmd_register(&bt_audio_cmd_bredr);
#if (A2DP_DEMO_SUPPORT == 1)
    cli_cmd_register(&bt_audio_cmd_a2dp);
    cli_cmd_register(&bt_audio_cmd_avrcp);
#endif

#if (HFP_DEMO_SUPPORT == 1)
    cli_cmd_register(&bt_audio_cmd_hfp);
#endif
}
```

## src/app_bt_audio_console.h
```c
/*
 * Copyright (c) 2026, Realtek Semiconductor Corporation
 *
 * SPDX-License-Identifier: LicenseRef-Realtek-5-Clause
 */

#ifndef _BT_AUDIO_CONSOLE_H_
#define _BT_AUDIO_CONSOLE_H_

#ifdef __cplusplus
extern "C" {
#endif /* __cplusplus */

/** @defgroup APP_BT_AUDIO_CONSOLE BT Audio Console
* @brief BT Audio command
* @{
*/

typedef enum
{
    GAP_BREDR_ID          = 0x0001,
    A2DP_ID               = 0x0002,
    AVRCP_ID              = 0x0003,
    HFP_ID                = 0x0004,
} T_BT_AUDIO_CMD_ID;

#define BT_AUDIO_ACTION_BREDR_LOCAL_ADDR_SET           0x01
#define BT_AUDIO_ACTION_BREDR_REMOTE_ADDR_SET          0x02
#define BT_AUDIO_ACTION_BREDR_NAME_SET                 0x03
#define BT_AUDIO_ACTION_BREDR_INQUIRY_START            0x04
#define BT_AUDIO_ACTION_BREDR_DEVICE_MODE_SET          0x05

#define BT_AUDIO_ACTION_A2DP_CONNECT           0x01
#define BT_AUDIO_ACTION_A2DP_DISCONNECT        0x02
#define BT_AUDIO_ACTION_A2DP_START             0x03
#define BT_AUDIO_ACTION_A2DP_SUSPEND           0x04
#define BT_AUDIO_ACTION_A2DP_VOLUME_UP         0x05
#define BT_AUDIO_ACTION_A2DP_VOLUME_DOWN       0x06

#define BT_AUDIO_ACTION_AVRCP_COVER_ART_CONNECT    0x01
#define BT_AUDIO_ACTION_AVRCP_COVER_ART_DISCONNECT 0x02
#define BT_AUDIO_ACTION_AVRCP_COVER_ART_GET        0x03
#define BT_AUDIO_ACTION_AVRCP_ELEM_ATTR_GET        0x04

#define BT_AUDIO_ACTION_HFP_CONNECT            0x01
#define BT_AUDIO_ACTION_HFP_DISCONNECT         0x02
#define BT_AUDIO_ACTION_HFP_SCO_CONNECT        0x03
#define BT_AUDIO_ACTION_HFP_SCO_DISCONNECT     0x04
#define BT_AUDIO_ACTION_HFP_CALL_INCOMING      0x05
#define BT_AUDIO_ACTION_HFP_CALL_ANSWER        0x06
#define BT_AUDIO_ACTION_HFP_CALL_TERMINATE     0x07
#define BT_AUDIO_ACTION_HFP_VENDOR_AT_CMD      0x08

void app_bt_audio_cmd_register(void);

/** @} End of APP_BT_AUDIO_CONSOLE */

#ifdef __cplusplus
}
#endif /* __cplusplus */

#endif /* _BT_AUDIO_CONSOLE_H_ */
```

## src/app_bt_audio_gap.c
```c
/*
 * Copyright (c) 2026, Realtek Semiconductor Corporation
 *
 * SPDX-License-Identifier: LicenseRef-Realtek-5-Clause
 */

#include <string.h>
#include "trace.h"
#include "console.h"
#include "btm.h"
#include "gap_br.h"
#include "bt_bond.h"
#include "app_bt_audio_link.h"
#include "app_bt_audio_gap.h"

static void app_bt_audio_gap_bt_cback(T_BT_EVENT event_type, void *event_buf, uint16_t buf_len)
{
    T_BT_EVENT_PARAM *param = event_buf;
    T_APP_BT_AUDIO_LINK *p_link;
    bool handle = true;

    switch (event_type)
    {
    case BT_EVENT_READY:
        {
#if (BT_AUDIO_DEMO_ROLE == 1)
            bt_inquiry_start(false, 10);
#endif
        }
        break;

    case BT_EVENT_INQUIRY_RESULT:
        {
            if (memcmp(app_db.remote_addr, param->inquiry_result.bd_addr, 6) == 0)
            {
                char *temp_buff = "Find Target Device!\r\n";
                console_write((uint8_t *)temp_buff, strlen(temp_buff));

                bt_inquiry_stop();
            }
        }
        break;

    case BT_EVENT_ACL_CONN_IND:
        {
            p_link = app_bt_audio_find_link(param->acl_conn_ind.bd_addr);
            if (p_link != NULL)
            {
                bt_acl_conn_reject(param->acl_conn_ind.bd_addr, BT_ACL_REJECT_UNACCEPTABLE_ADDR);
            }
            else
            {
                bt_acl_conn_accept(param->acl_conn_ind.bd_addr, BT_LINK_ROLE_SLAVE);
            }
        }
        break;

    case BT_EVENT_LINK_KEY_REQ:
        {
            uint8_t link_key[16];
            T_BT_LINK_KEY_TYPE type;

            if (bt_bond_key_get(param->link_key_req.bd_addr, link_key, (uint8_t *)&type))
            {
                bt_link_key_cfm(param->link_key_req.bd_addr, true, type, link_key);
            }
            else
            {
                bt_link_key_cfm(param->link_key_req.bd_addr, false, type, link_key);
            }
        }
        break;

    case BT_EVENT_LINK_PIN_CODE_REQ:
        {
            uint8_t pin_code[4] = {1, 2, 3, 4};
            bt_link_pin_code_cfm(param->link_pin_code_req.bd_addr, pin_code, 4, true);
        }
        break;

    case BT_EVENT_LINK_USER_CONFIRMATION_REQ:
        {
            gap_br_user_cfm_req_cfm(param->link_user_confirmation_req.bd_addr, GAP_CFM_CAUSE_ACCEPT);
        }
        break;

    case BT_EVENT_ACL_CONN_SUCCESS:
        {
            app_bt_audio_alloc_link(param->acl_conn_success.bd_addr);
            bt_device_mode_set(BT_DEVICE_MODE_IDLE);
            bt_active_link_set(param->acl_conn_success.bd_addr);
        }
        break;

    case BT_EVENT_ACL_CONN_DISCONN:
        {
            p_link = app_bt_audio_find_link(param->acl_conn_disconn.bd_addr);
            if (p_link != NULL)
            {
                app_bt_audio_free_link(p_link);
            }

            bt_device_mode_set(BT_DEVICE_MODE_DISCOVERABLE_CONNECTABLE);
        }
        break;

    default:
        handle = false;
        break;
    }

    if (handle == true)
    {
        APP_PRINT_INFO1("app_bt_audio_gap_bt_cback: event_type 0x%04x", event_type);
    }
}

void app_bt_audio_gap_local_addr_set(uint8_t *bd_addr)
{
    gap_set_bd_addr(bd_addr);
}

void app_bt_audio_gap_remote_addr_set(uint8_t *bd_addr)
{
    memcpy(app_db.remote_addr, bd_addr, 6);
}

bool app_bt_audio_gap_local_bt_name_set(uint8_t *p_name, uint8_t  len)
{
    return bt_local_name_set(p_name, len);
}

bool app_bt_audio_gap_inquiry_start(void)
{
    return bt_inquiry_start(false, 10);
}

bool app_bt_audio_gap_device_mode_set(uint8_t value)
{
    return bt_device_mode_set((T_BT_DEVICE_MODE)value);
}

void app_bt_audio_gap_init(void)
{
    bt_mgr_cback_register(app_bt_audio_gap_bt_cback);
}
```

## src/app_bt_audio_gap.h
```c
/*
 * Copyright (c) 2026, Realtek Semiconductor Corporation
 *
 * SPDX-License-Identifier: LicenseRef-Realtek-5-Clause
 */

#ifndef _BT_AUDIO_GAP_H_
#define _BT_AUDIO_GAP_H_

#ifdef __cplusplus
extern "C" {
#endif /* __cplusplus */

/** @defgroup BT_AUDIO_GAP BT Audio Gap
  * @brief BT Audio Gap
  * @{
  */

/*============================================================================*
 *                              Functions
 *============================================================================*/
void app_bt_audio_gap_local_addr_set(uint8_t *bd_addr);

void app_bt_audio_gap_remote_addr_set(uint8_t *bd_addr);

bool app_bt_audio_gap_local_bt_name_set(uint8_t *p_name, uint8_t  len);

bool app_bt_audio_gap_inquiry_start(void);

bool app_bt_audio_gap_device_mode_set(uint8_t value);

void app_bt_audio_gap_init(void);

/** @} End of BT_AUDIO_GAP_Exported_Functions */

/** @} End of BT_AUDIO_GAP */

#ifdef __cplusplus
}
#endif /* __cplusplus */

#endif /* _BT_AUDIO_GAP_H_ */
```

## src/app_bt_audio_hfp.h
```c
/*
 * Copyright (c) 2026, Realtek Semiconductor Corporation
 *
 * SPDX-License-Identifier: LicenseRef-Realtek-5-Clause
 */

#ifndef _APP_BT_AUDIO_HFP_H_
#define _APP_BT_AUDIO_HFP_H_

#ifdef __cplusplus
extern "C" {
#endif /* __cplusplus */

/** @defgroup APP_BT_AUDIO_HFP BT Audio HFP
* @brief APP BT Audio HFP
* @{
*/

/*============================================================================*
 *                         Macros
 *============================================================================*/
/** @addtogroup APP_BT_AUDIO_HFP_Exported_Macros BT Audio HFP Exported Macros
  * @brief
  * @{
  */

#define BT_AUDIO_HFP_ROLE_HF  0
#define BT_AUDIO_HFP_ROLE_AG  1

/** End of APP_BT_AUDIO_HFP_Exported_Macros
* @}
*/

/*============================================================================*
 *                         Functions
 *============================================================================*/
/** @defgroup APP_BT_AUDIO_HFP_Exported_Functions BT Audio HFP Exported Functions
  * @brief
  * @{
  */

void app_bt_audio_hfp_init(uint8_t role);

bool app_bt_audio_hfp_sco_connect(uint8_t *bd_addr);

bool app_bt_audio_hfp_sco_disconnect(uint8_t *bd_addr);

bool app_bt_audio_hfp_connect(uint8_t *bd_addr);

bool app_bt_audio_hfp_disconnect(uint8_t *bd_addr);

bool app_bt_audio_hfp_call_incoming(uint8_t *bd_addr);

bool app_bt_audio_hfp_call_answer(uint8_t *bd_addr);

bool app_bt_audio_hfp_call_terminate(uint8_t *bd_addr);

bool app_bt_audio_hfp_vendor_at_cmd(uint8_t *bd_addr);

/** @} End of APP_BT_AUDIO_HFP_Exported_Functions */

/** @} End of APP_BT_AUDIO_HFP */

#ifdef __cplusplus
}
#endif /* __cplusplus */

#endif /* _APP_BT_AUDIO_HFP_H_ */
```
